# MK50DZ10 register map
Vendor: Freescale Semiconductor, Inc.; Series: Kinetis_K; File version: 1.6
CPU: CM4 r0p1, little endian, no MPU, no FPU, VTOR, 4 interrupt priority bits
Registers are 32-bit, read-write, reset 0x0 unless marked. A register's access mark holds for its fields unless they carry their own. Offsets are from the block's base; [hi:lo] are bit positions; {n}, {i} and the like mark numbered series.

## FTFL — Flash Memory Interface
Base 0x40020000; register names take the prefix FTFL_
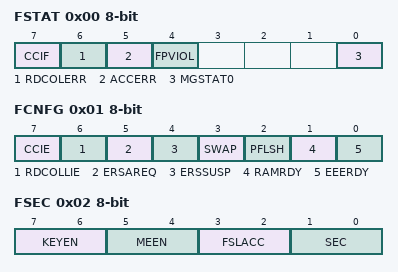
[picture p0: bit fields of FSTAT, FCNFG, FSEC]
0x00 FSTAT 8-bit — Flash Status Register
  [7] CCIF — Command Complete Interrupt Flag
    0=FTFL command in progress; 1=FTFL command has completed
  [6] RDCOLERR — FTFL Read Collision Error Flag
    0=No collision error detected; 1=Collision error detected
  [5] ACCERR — Flash Access Error Flag
    0=No access error detected; 1=Access error detected
  [4] FPVIOL — Flash Protection Violation Flag
    0=No protection violation detected; 1=Protection violation detected
  [0] MGSTAT0 ro — Memory Controller Command Completion Status Flag
0x01 FCNFG 8-bit — Flash Configuration Register
  [7] CCIE — Command Complete Interrupt Enable
    0=Command complete interrupt disabled; 1=Command complete interrupt enabled. An interrupt request is generated whenever the FSTAT[CCIF] flag is set.
  [6] RDCOLLIE — Read Collision Error Interrupt Enable
    0=Read collision error interrupt disabled; 1=Read collision error interrupt enabled. An interrupt request is generated whenever an FTFL read collision error is detected (see the description of FSTAT[RDCOLERR]).
  [5] ERSAREQ ro — Erase All Request
    0=No request or request complete; 1=Request to: run the Erase All Blocks command, verify the erased state, program the security byte in the Flash Configuration Field to the unsecure state, and release MCU security by setting the FSEC[SEC] field to the unsecure state
  [4] ERSSUSP — Erase Suspend
    0=No suspend requested; 1=Suspend the current Erase Flash Sector command execution
  [3] SWAP ro
    0=Physical program flash 0 is located at relative address 0x0000; 1=If the PFLSH flag is set, physical program flash 1 is located at relative address 0x0000. If the PFLSH flag is not set, physical program flash 0 is located at relative address 0x0000
  [2] PFLSH ro — FTFL configuration
    1=FTFL configured for program flash only, without support for data flash and/or EEPROM
  [1] RAMRDY ro — RAM Ready
    0=Programming acceleration RAM is not available; 1=Programming acceleration RAM is available
  [0] EEERDY ro
0x02 FSEC 8-bit ro reset not defined — Flash Security Register
  [7:6] KEYEN — Backdoor Key Security Enable
    0=Backdoor key access disabled; 1=Backdoor key access disabled (preferred KEYEN state to disable backdoor key access); 2=Backdoor key access enabled; 3=Backdoor key access disabled
  [5:4] MEEN — Mass Erase Enable Bits
    0=Mass erase is enabled; 1=Mass erase is enabled; 2=Mass erase is disabled; 3=Mass erase is enabled
  [3:2] FSLACC — Freescale Failure Analysis Access Code
    0=Freescale factory access granted; 1=Freescale factory access denied; 2=Freescale factory access denied; 3=Freescale factory access granted
  [1:0] SEC — Flash Security
    0=MCU security status is secure; 1=MCU security status is secure; 2=MCU security status is unsecure (The standard shipping condition of the FTFL is unsecure.); 3=MCU security status is secure
0x03 FOPT 8-bit ro reset not defined — Flash Option Register
  [7:0] OPT — Nonvolatile Option
0x04 FCCOB{x} (x=3,2,1,0,7,6,5,4,B,A,9,8; step 0x1) 8-bit — Flash Common Command Object Registers
  [7:0] CCOBn
0x10 FPROT{x} (x=3,2,1,0; step 0x1) 8-bit reset not defined — Program Flash Protection Registers
  [7:0] PROT — Program Flash Region Protect
    0=Program flash region is protected; 1=Program flash region is not protected

## DMAMUX — DMA channel multiplexor
Base 0x40021000; register names take the prefix DMAMUX_
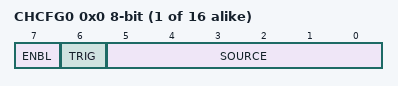
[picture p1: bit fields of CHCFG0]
{0x0+i} CHCFG{i} (i=0..15) 8-bit — Channel Configuration Register
  [7] ENBL — DMA Channel Enable
    0=DMA channel is disabled. This mode is primarily used during configuration of the DMA Mux. The DMA has separate channel enables/disables, which should be used to disable or re-configure a DMA channel.; 1=DMA channel is enabled
  [6] TRIG — DMA Channel Trigger Enable
    0=Triggering is disabled. If triggering is disabled, and the ENBL bit is set, the DMA Channel will simply route the specified source to the DMA channel. (normal mode); 1=Triggering is enabled. If triggering is enabled, and the ENBL bit is set, the DMAMUX is in periodic trigger mode.
  [5:0] SOURCE — DMA Channel Source (slot)
